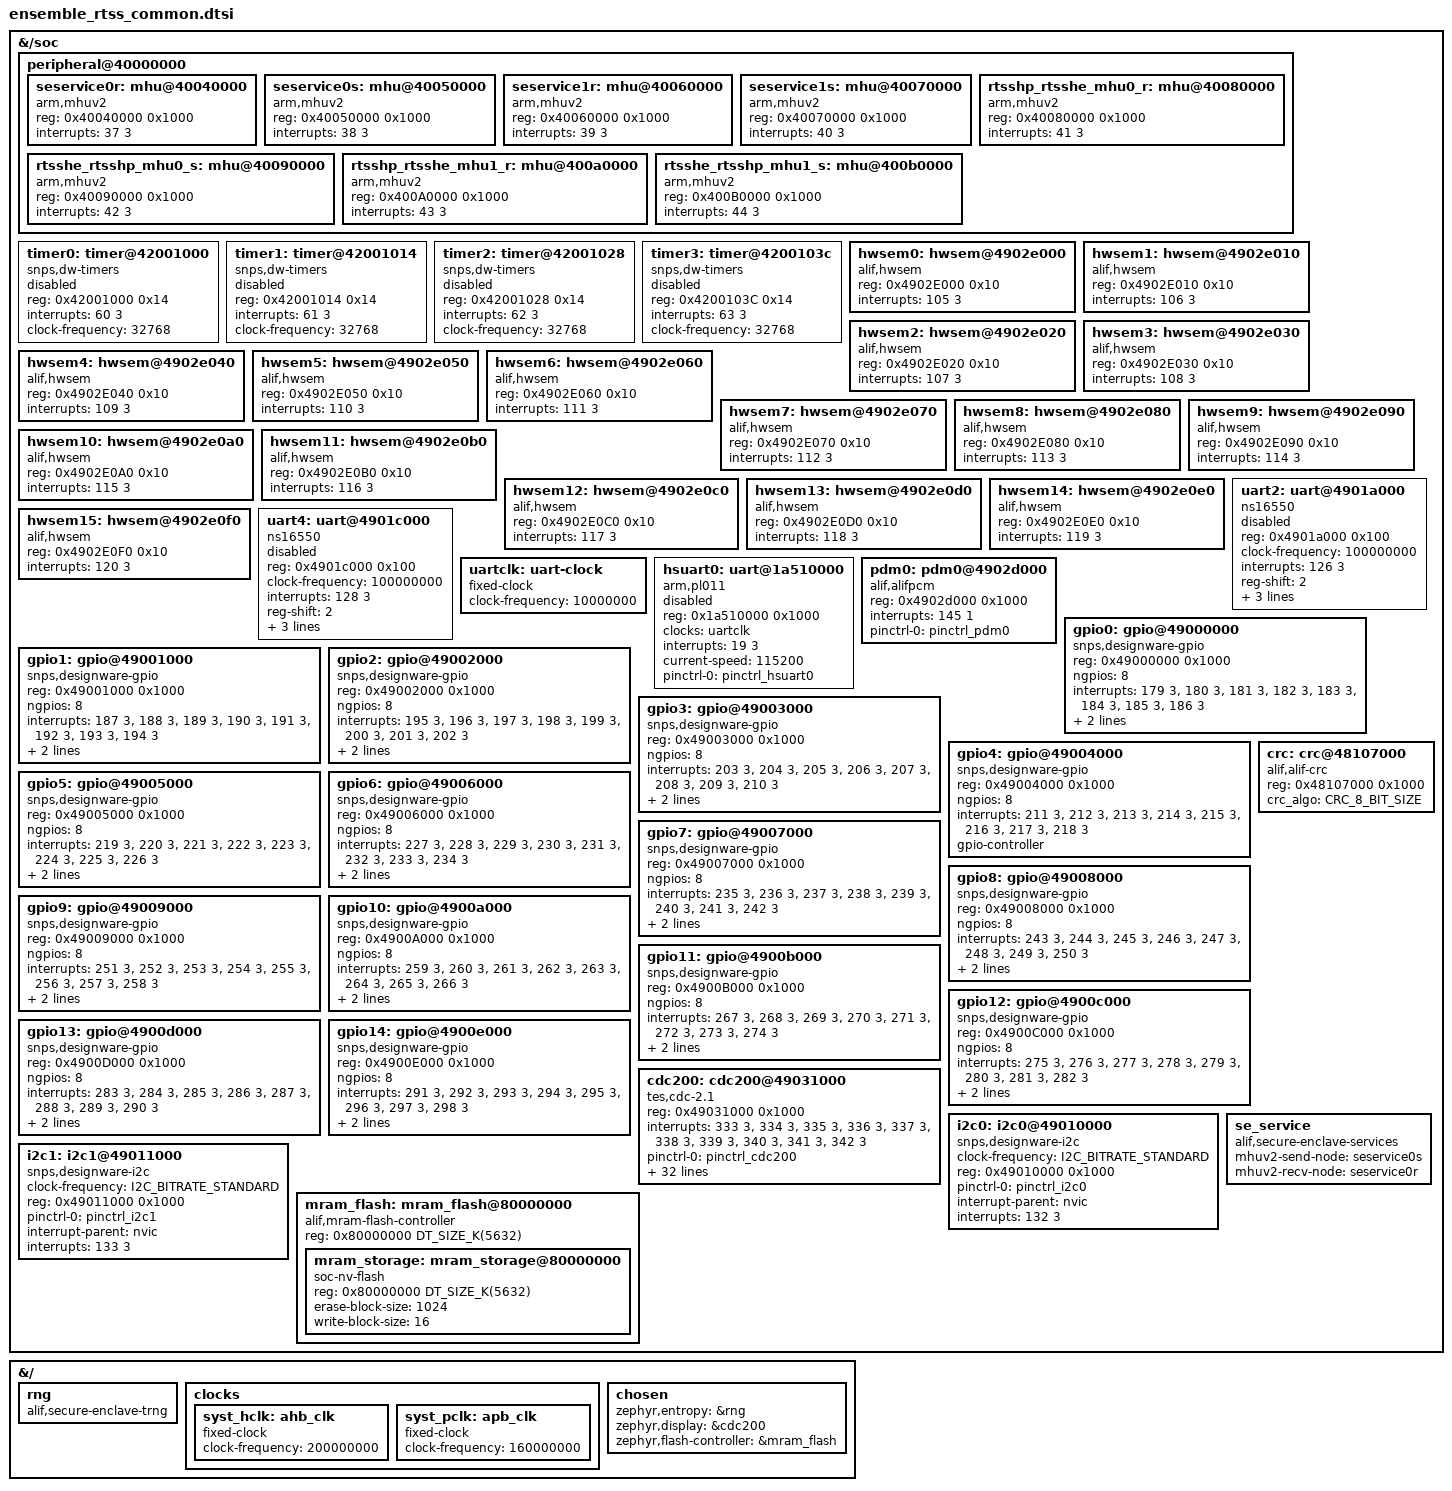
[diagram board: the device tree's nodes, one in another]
/* Copyright (c) 2024 Alif Semiconductor
 *
 * SPDX-License-Identifier: Apache-2.0
 */
#include <arm/armv8.1-m.dtsi>
#include <mem.h>
#include <zephyr/dt-bindings/i2c/i2c.h>
#include <zephyr/dt-bindings/gpio/gpio.h>
&{/soc} {
	peripheral@40000000 {
		#address-cells = < 0x1 >;
		#size-cells = < 0x1 >;
		ranges = < 0x0 0x40000000 0x2000000 >;

		seservice0r: mhu@40040000 {
			compatible = "arm,mhuv2";
			reg = < 0x40040000 0x1000 >;
			interrupts = < 37 3 >;
			interrupt-names = "rx";
		};
		seservice0s: mhu@40050000 {
			compatible = "arm,mhuv2";
			reg = < 0x40050000 0x1000 >;
			interrupts = < 38 3 >;
			interrupt-names = "tx";
		};
		seservice1r: mhu@40060000 {
			compatible = "arm,mhuv2";
			reg = < 0x40060000 0x1000 >;
			interrupts = < 39 3 >;
			interrupt-names = "rx";
		};
		seservice1s: mhu@40070000 {
			compatible = "arm,mhuv2";
			reg = < 0x40070000 0x1000 >;
			interrupts = < 40 3 >;
			interrupt-names = "tx";
		};
		rtsshp_rtsshe_mhu0_r: mhu@40080000 {
			compatible = "arm,mhuv2";
			reg = < 0x40080000 0x1000 >;
			interrupts = < 41 3 >;
			interrupt-names = "rx";
		};
		rtsshe_rtsshp_mhu0_s: mhu@40090000 {
			compatible = "arm,mhuv2";
			reg = < 0x40090000 0x1000 >;
			interrupts = < 42 3 >;
			interrupt-names = "tx";
		};
		rtsshp_rtsshe_mhu1_r: mhu@400a0000 {
			compatible = "arm,mhuv2";
			reg = < 0x400A0000 0x1000 >;
			interrupts = < 43 3 >;
			interrupt-names = "rx";
		};
		rtsshe_rtsshp_mhu1_s: mhu@400b0000 {
			compatible = "arm,mhuv2";
			reg = < 0x400B0000 0x1000 >;
			interrupts = < 44 3 >;
			interrupt-names = "tx";
		};
	};

	timer0: timer@42001000 {
		compatible = "snps,dw-timers";
		reg = <0x42001000 0x14>;
		interrupts = < 60 3 >;
		clock-frequency = <32768>;
		status = "disabled";
	};

	timer1: timer@42001014 {
		compatible = "snps,dw-timers";
		reg = <0x42001014 0x14>;
		interrupts = < 61 3 >;
		clock-frequency = <32768>;
		status = "disabled";
	};

	timer2: timer@42001028 {
		compatible = "snps,dw-timers";
		reg = <0x42001028 0x14>;
		interrupts = < 62 3 >;
		clock-frequency = <32768>;
		status = "disabled";
	};

	timer3: timer@4200103c {
		compatible = "snps,dw-timers";
		reg = <0x4200103C 0x14>;
		interrupts = < 63 3 >;
		clock-frequency = <32768>;
		status = "disabled";
	};

	hwsem0: hwsem@4902e000 {
		compatible = "alif,hwsem";
		reg = <0x4902E000 0x10>;
		interrupts = < 105 3 >;
	};
	hwsem1: hwsem@4902e010 {
		compatible = "alif,hwsem";
		reg = <0x4902E010 0x10>;
		interrupts = < 106 3 >;
	};
	hwsem2: hwsem@4902e020 {
		compatible = "alif,hwsem";
		reg = <0x4902E020 0x10>;
		interrupts = < 107 3 >;
	};
	hwsem3: hwsem@4902e030 {
		compatible = "alif,hwsem";
		reg = <0x4902E030 0x10>;
		interrupts = < 108 3 >;
	};
	hwsem4: hwsem@4902e040 {
		compatible = "alif,hwsem";
		reg = <0x4902E040 0x10>;
		interrupts = < 109 3 >;
	};
	hwsem5: hwsem@4902e050 {
		compatible = "alif,hwsem";
		reg = <0x4902E050 0x10>;
		interrupts = < 110 3 >;
	};
	hwsem6: hwsem@4902e060 {
		compatible = "alif,hwsem";
		reg = <0x4902E060 0x10>;
		interrupts = < 111 3 >;
	};
	hwsem7: hwsem@4902e070 {
		compatible = "alif,hwsem";
		reg = <0x4902E070 0x10>;
		interrupts = < 112 3 >;
	};
	hwsem8: hwsem@4902e080 {
		compatible = "alif,hwsem";
		reg = <0x4902E080 0x10>;
		interrupts = < 113 3 >;
	};
	hwsem9: hwsem@4902e090 {
		compatible = "alif,hwsem";
		reg = <0x4902E090 0x10>;
		interrupts = < 114 3 >;
	};
	hwsem10: hwsem@4902e0a0 {
		compatible = "alif,hwsem";
		reg = <0x4902E0A0 0x10>;
		interrupts = < 115 3 >;
	};
	hwsem11: hwsem@4902e0b0 {
		compatible = "alif,hwsem";
		reg = <0x4902E0B0 0x10>;
		interrupts = < 116 3 >;
	};
	hwsem12: hwsem@4902e0c0 {
		compatible = "alif,hwsem";
		reg = <0x4902E0C0 0x10>;
		interrupts = < 117 3 >;
	};
	hwsem13: hwsem@4902e0d0 {
		compatible = "alif,hwsem";
		reg = <0x4902E0D0 0x10>;
		interrupts = < 118 3 >;
	};
	hwsem14: hwsem@4902e0e0 {
		compatible = "alif,hwsem";
		reg = <0x4902E0E0 0x10>;
		interrupts = < 119 3 >;
	};
	hwsem15: hwsem@4902e0f0 {
		compatible = "alif,hwsem";
		reg = <0x4902E0F0 0x10>;
		interrupts = < 120 3 >;
	};

	uart2: uart@4901a000 {
		compatible = "ns16550";
		reg = <0x4901a000 0x100>;
		/* 100Mhz baud clock */
		clock-frequency = <100000000>;
		interrupts = <126 3>;
		reg-shift = <2>;
		current-speed = <115200>;
		pinctrl-0 = < &pinctrl_uart2 >;
		pinctrl-names = "default";
		fifo-size = <32>;
		status = "disabled";
	};

	uart4: uart@4901c000 {
		compatible = "ns16550";
		reg = <0x4901c000 0x100>;
		/* 100Mhz baud clock */
		clock-frequency = <100000000>;
		interrupts = <128 3>;
		reg-shift = <2>;
		current-speed = <115200>;
		pinctrl-0 = < &pinctrl_uart4 >;
		pinctrl-names = "default";
		fifo-size = <32>;
		status = "disabled";
	};

	uartclk: uart-clock {
		compatible = "fixed-clock";
		clock-frequency = <10000000>;
		#clock-cells = <0>;
	};

	hsuart0:uart@1a510000 {
		compatible = "arm,pl011";
		reg = <0x1a510000 0x1000>;
		clocks = <&uartclk>;
		interrupts = <19 3>;
		interrupt-names = "rx";
		current-speed = <115200>;
		pinctrl-0 = < &pinctrl_hsuart0 >;
		pinctrl-names = "default";
		status = "disabled";
	};

	pdm0: pdm0@4902d000 {
		compatible = "alif,alifpcm";
		reg = <0x4902d000 0x1000>;
		interrupts = <145 1>;
		pinctrl-0 = < &pinctrl_pdm0 >;
		pinctrl-names = "default";
		status = "okay";
	};


	gpio0: gpio@49000000 {
		compatible = "snps,designware-gpio";
		reg = <0x49000000 0x1000>;
		ngpios = <8>;
		interrupts = <179 3>, <180 3>,
			     <181 3>, <182 3>,
			     <183 3>, <184 3>,
			     <185 3>, <186 3>;
		pinctrl-0 = < &pinctrl_gpio0 >;
		pinctrl-names = "default";
		gpio-controller;
		#gpio-cells = <2>;
	};
	gpio1: gpio@49001000 {
		compatible = "snps,designware-gpio";
		reg = <0x49001000 0x1000>;
		ngpios = <8>;
		interrupts = <187 3>, <188 3>,
			     <189 3>, <190 3>,
			     <191 3>, <192 3>,
			     <193 3>, <194 3>;
		pinctrl-0 = < &pinctrl_gpio1 >;
		pinctrl-names = "default";
		gpio-controller;
		#gpio-cells = <2>;
	};
	gpio2: gpio@49002000 {
		compatible = "snps,designware-gpio";
		reg = <0x49002000 0x1000>;
		ngpios = <8>;
		interrupts = <195 3>, <196 3>,
			     <197 3>, <198 3>,
			     <199 3>, <200 3>,
			     <201 3>, <202 3>;
		pinctrl-0 = < &pinctrl_gpio2 >;
		pinctrl-names = "default";
		gpio-controller;
		#gpio-cells = <2>;
	};
	gpio3: gpio@49003000 {
		compatible = "snps,designware-gpio";
		reg = <0x49003000 0x1000>;
		ngpios = <8>;
		interrupts = <203 3>, <204 3>,
			     <205 3>, <206 3>,
			     <207 3>, <208 3>,
			     <209 3>, <210 3>;
		pinctrl-0 = < &pinctrl_gpio3 >;
		pinctrl-names = "default";
		gpio-controller;
		#gpio-cells = <2>;
	};
	gpio4: gpio@49004000 {
		compatible = "snps,designware-gpio";
		reg = <0x49004000 0x1000>;
		ngpios = <8>;
		interrupts = <211 3>, <212 3>,
			     <213 3>, <214 3>,
			     <215 3>, <216 3>,
			     <217 3>, <218 3>;
	/*	Commenting this here as gpio 4 is used for
	 *	jtag connection
	 *
	 *	pinctrl-0 = < &pinctrl_gpio4 >;
	 *	pinctrl-names = "default";
	 */
		gpio-controller;
		#gpio-cells = <2>;
	};
	gpio5: gpio@49005000 {
		compatible = "snps,designware-gpio";
		reg = <0x49005000 0x1000>;
		ngpios = <8>;
		interrupts = <219 3>, <220 3>,
			     <221 3>, <222 3>,
			     <223 3>, <224 3>,
			     <225 3>, <226 3>;
		pinctrl-0 = < &pinctrl_gpio5 >;
		pinctrl-names = "default";
		gpio-controller;
		#gpio-cells = <2>;
	};
	gpio6: gpio@49006000 {
		compatible = "snps,designware-gpio";
		reg = <0x49006000 0x1000>;
		ngpios = <8>;
		interrupts = <227 3>, <228 3>,
			     <229 3>, <230 3>,
			     <231 3>, <232 3>,
			     <233 3>, <234 3>;
		pinctrl-0 = < &pinctrl_gpio6 >;
		pinctrl-names = "default";
		gpio-controller;
		#gpio-cells = <2>;
	};
	gpio7: gpio@49007000 {
		compatible = "snps,designware-gpio";
		reg = <0x49007000 0x1000>;
		ngpios = <8>;
		interrupts = <235 3>, <236 3>,
			     <237 3>, <238 3>,
			     <239 3>, <240 3>,
			     <241 3>, <242 3>;
		pinctrl-0 = < &pinctrl_gpio7 >;
		pinctrl-names = "default";
		gpio-controller;
		#gpio-cells = <2>;
	};

	gpio8: gpio@49008000 {
		compatible = "snps,designware-gpio";
		reg = <0x49008000 0x1000>;
		ngpios = <8>;
		interrupts = <243 3>, <244 3>,
			     <245 3>, <246 3>,
			     <247 3>, <248 3>,
			     <249 3>, <250 3>;
		pinctrl-0 = < &pinctrl_gpio8 >;
		pinctrl-names = "default";
		gpio-controller;
		#gpio-cells = <2>;
	};
	gpio9: gpio@49009000 {
		compatible = "snps,designware-gpio";
		reg = <0x49009000 0x1000>;
		ngpios = <8>;
		interrupts = <251 3>, <252 3>,
			     <253 3>, <254 3>,
			     <255 3>, <256 3>,
			     <257 3>, <258 3>;
		pinctrl-0 = < &pinctrl_gpio9 >;
		pinctrl-names = "default";
		gpio-controller;
		#gpio-cells = <2>;
	};
	gpio10: gpio@4900a000 {
		compatible = "snps,designware-gpio";
		reg = <0x4900A000 0x1000>;
		ngpios = <8>;
		interrupts = <259 3>, <260 3>,
			     <261 3>, <262 3>,
			     <263 3>, <264 3>,
			     <265 3>, <266 3>;
		pinctrl-0 = < &pinctrl_gpio10 >;
		pinctrl-names = "default";
		gpio-controller;
		#gpio-cells = <2>;
	};
	gpio11: gpio@4900b000 {
		compatible = "snps,designware-gpio";
		reg = <0x4900B000 0x1000>;
		ngpios = <8>;
		interrupts = <267 3>, <268 3>,
			     <269 3>, <270 3>,
			     <271 3>, <272 3>,
			     <273 3>, <274 3>;
		pinctrl-0 = < &pinctrl_gpio11 >;
		pinctrl-names = "default";
		gpio-controller;
		#gpio-cells = <2>;
	};
	gpio12: gpio@4900c000 {
		compatible = "snps,designware-gpio";
		reg = <0x4900C000 0x1000>;
		ngpios = <8>;
		interrupts = <275 3>, <276 3>,
			     <277 3>, <278 3>,
			     <279 3>, <280 3>,
			     <281 3>, <282 3>;
		pinctrl-0 = < &pinctrl_gpio12 >;
		pinctrl-names = "default";
		gpio-controller;
		#gpio-cells = <2>;
	};
	gpio13: gpio@4900d000 {
		compatible = "snps,designware-gpio";
		reg = <0x4900D000 0x1000>;
		ngpios = <8>;
		interrupts = <283 3>, <284 3>,
			     <285 3>, <286 3>,
			     <287 3>, <288 3>,
			     <289 3>, <290 3>;
		pinctrl-0 = < &pinctrl_gpio13 >;
		pinctrl-names = "default";
		gpio-controller;
		#gpio-cells = <2>;
	};
	gpio14: gpio@4900e000 {
		compatible = "snps,designware-gpio";
		reg = <0x4900E000 0x1000>;
		ngpios = <8>;
		interrupts = <291 3>, <292 3>,
			     <293 3>, <294 3>,
			     <295 3>, <296 3>,
			     <297 3>, <298 3>;
		pinctrl-0 = < &pinctrl_gpio14 >;
		pinctrl-names = "default";
		gpio-controller;
		#gpio-cells = <2>;
	};

	crc: crc@48107000 {
		compatible = "alif,alif-crc";
		reg = <0x48107000 0x1000>;
		crc_algo = "CRC_8_BIT_SIZE";
		status = "okay";
	};

	cdc200: cdc200@49031000 {
		compatible = "tes,cdc-2.1";
		reg = <0x49031000 0x1000>;
		status = "okay";
		interrupts =	<333 3>,
				<334 3>,
				<335 3>,
				<336 3>,
				<337 3>,
				<338 3>,
				<339 3>,
				<340 3>,
				<341 3>,
				<342 3>;
		interrupt-names = "scanline_0",
				  "scanline_1",
				  "fifo_warning_0",
				  "fifo_warning_1",
				  "fifo_underrun_0",
				  "fifo_underrun_1",
				  "bus_error_0",
				  "bus_error_1",
				  "reg_reload_0",
				  "reg_reload_1";
		pinctrl-0 = < &pinctrl_cdc200 >;
		pinctrl-names = "default";

		/* Panel Config */
		width = <800>;
		height = <480>;
		hfront-porch = <210>;
		hback-porch = <46>;
		hsync-len = <1>;
		vfront-porch = <22>;
		vback-porch = <23>;
		vsync-len = <1>;
		hsync-active = <0>;
		vsync-active = <0>;
		de-active = <1>;
		pixelclk-active = <0>;
		/* BG Layer color is 24-bit in size. */
		bg-color = <0x5a5a5a>;

		/* Layer 0 Config */
		enable-l1 = <1>;
		pixel-fmt-l1 = "rgb-565";
		/* Default color for Layer is 32-bit in size. */
		def-back-color-l1 = <0x00ff00>;
		win-x0-l1 = <0>;
		win-y0-l1 = <0>;
		win-x1-l1 = <300>;
		win-y1-l1 = <480>;
		blend-factor1-l1 = <4>;
		blend-factor2-l1 = <5>;
		const-alpha-l1 = <0x7f>;

		/* Layer 1 Config */
		enable-l2 = <1>;
		pixel-fmt-l2 = "argb-8888";
		win-x0-l2 = <500>;
		win-y0-l2 = <0>;
		win-x1-l2 = <800>;
		win-y1-l2 = <68>;
		blend-factor1-l2 = <4>;
		blend-factor2-l2 = <5>;
		const-alpha-l2 = <0xaf>;
	};
	i2c0: i2c0@49010000 {
		compatible = "snps,designware-i2c";
		clock-frequency = <I2C_BITRATE_STANDARD>;
		#address-cells = <1>;
		#size-cells = <0>;
		reg = <0x49010000 0x1000>;
		pinctrl-0 = < &pinctrl_i2c0 >;
		pinctrl-names = "default";
		interrupt-parent = <&nvic>;
		interrupts = <132 3>;
		status = "okay";
	};
	i2c1: i2c1@49011000 {
		compatible = "snps,designware-i2c";
		clock-frequency = <I2C_BITRATE_STANDARD>;
		#address-cells = <1>;
		#size-cells = <0>;
		reg = <0x49011000 0x1000>;
		pinctrl-0 = < &pinctrl_i2c1 >;
		pinctrl-names = "default";
		interrupt-parent = <&nvic>;
		interrupts = <133 3>;
		status = "okay";
	};

	se_service: se_service {
		compatible = "alif,secure-enclave-services";
		mhuv2-send-node = <&seservice0s>;
		mhuv2-recv-node = <&seservice0r>;
		status = "okay";
	};
	mram_flash: mram_flash@80000000 {
		compatible = "alif,mram-flash-controller";
		/* Usable MRAM size for applications is 5632 KB */
		reg = <0x80000000 DT_SIZE_K(5632)>;

		#address-cells = <1>;
		#size-cells = <1>;
		mram_storage: mram_storage@80000000 {
			compatible = "soc-nv-flash";
			reg = <0x80000000 DT_SIZE_K(5632)>;
			erase-block-size = <1024>;
			write-block-size = <16>;
		};
	};
};

&{/} {
	rng: rng {
		status = "okay";
		compatible = "alif,secure-enclave-trng";
	};
	clocks {
		syst_hclk: ahb_clk {
			compatible = "fixed-clock";
			clock-frequency = <200000000>;
			#clock-cells = <0>;
		};
		syst_pclk: apb_clk {
			compatible = "fixed-clock";
			clock-frequency = <160000000>;
			#clock-cells = <0>;
		};
	};

	chosen {
		zephyr,entropy = &rng;
		zephyr,display = &cdc200;
		zephyr,flash-controller = &mram_flash;
	};
};
